# ESP32-C61 register map
Vendor: ESPRESSIF SYSTEMS (SHANGHAI) CO., LTD.; Series: ESP32 C-Series; File version: 1
CPU: RV32IMAC r0p0, little endian, no MPU, no FPU, 0 interrupt priority bits
Address unit: 32 bits
Registers are 32-bit, read-write, reset 0x0 unless marked. A register's access mark holds for its fields unless they carry their own. Offsets are from the block's base; [hi:lo] are bit positions.

## BUS_MONITOR — BUS_MONITOR Peripheral
Base 0x600C2000
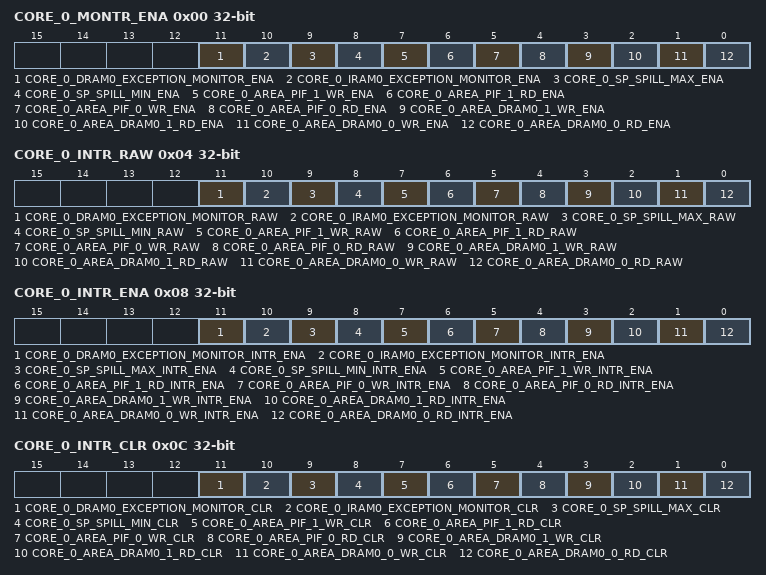
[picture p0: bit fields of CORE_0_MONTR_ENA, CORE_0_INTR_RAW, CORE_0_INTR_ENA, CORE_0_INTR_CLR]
0x00 CORE_0_MONTR_ENA — core0 monitor enable configuration register
  [11] CORE_0_DRAM0_EXCEPTION_MONITOR_ENA — DBUS busy monitor enbale
  [10] CORE_0_IRAM0_EXCEPTION_MONITOR_ENA — IBUS busy monitor enable
  [9] CORE_0_SP_SPILL_MAX_ENA — Configures whether to monitor SP exceeding the upper bound address of SP monitored region.\\ 0: Not Monitor\\ 1: Monitor\\
  [8] CORE_0_SP_SPILL_MIN_ENA — Configures whether to monitor SP exceeding the lower bound address of SP monitored region.\\ 0: Not Monitor\\ 1: Monitor\\
  [7] CORE_0_AREA_PIF_1_WR_ENA — Configures whether to monitor write operations in region 1 by the Peripheral bus.\\ 0: Not Monitor\\ 1: Monitor\\
  [6] CORE_0_AREA_PIF_1_RD_ENA — Configures whether to monitor read operations in region 1 by the Peripheral bus.\\ 0: Not Monitor\\ 1: Monitor\\
  [5] CORE_0_AREA_PIF_0_WR_ENA — Configures whether to monitor write operations in region 0 by the Peripheral bus.\\ 0: Not Monitor\\ 1: Monitor\\
  [4] CORE_0_AREA_PIF_0_RD_ENA — Configures whether to monitor read operations in region 0 by the Peripheral bus.\\ 0: Not Monitor\\ 1: Monitor\\
  [3] CORE_0_AREA_DRAM0_1_WR_ENA — Configures whether to monitor write operations in region 1 by the Data bus.\\ 0: Not Monitor\\ 1: Monitor\\
  [2] CORE_0_AREA_DRAM0_1_RD_ENA — Configures whether to monitor read operations in region 1 by the Data bus.\\ 0: Not Monitor\\ 1: Monitor\\
  [1] CORE_0_AREA_DRAM0_0_WR_ENA — Configures whether to monitor write operations in region 0 by the Data bus.\\ 0: Not monitor\\ 1: Monitor\\
  [0] CORE_0_AREA_DRAM0_0_RD_ENA — Configures whether to monitor read operations in region 0 by the Data bus. \\ 0: Not monitor\\ 1: Monitor\\
0x04 CORE_0_INTR_RAW ro — core0 monitor interrupt status register
  [11] CORE_0_DRAM0_EXCEPTION_MONITOR_RAW — DBUS busy monitor initerrupt status
  [10] CORE_0_IRAM0_EXCEPTION_MONITOR_RAW — IBUS busy monitor interrupt status
  [9] CORE_0_SP_SPILL_MAX_RAW — The raw interrupt status of SP exceeding the upper bound address of SP monitored region.
  [8] CORE_0_SP_SPILL_MIN_RAW — The raw interrupt status of SP exceeding the lower bound address of SP monitored region.
  [7] CORE_0_AREA_PIF_1_WR_RAW — The raw interrupt status of write operations in region 1 by Peripheral bus.
  [6] CORE_0_AREA_PIF_1_RD_RAW — The raw interrupt status of read operations in region 1 by Peripheral bus.
  [5] CORE_0_AREA_PIF_0_WR_RAW — The raw interrupt status of write operations in region 0 by Peripheral bus.
  [4] CORE_0_AREA_PIF_0_RD_RAW — The raw interrupt status of read operations in region 0 by Peripheral bus.
  [3] CORE_0_AREA_DRAM0_1_WR_RAW — The raw interrupt status of write operations in region 1 by Data bus.
  [2] CORE_0_AREA_DRAM0_1_RD_RAW — The raw interrupt status of read operations in region 1 by Data bus.
  [1] CORE_0_AREA_DRAM0_0_WR_RAW — The raw interrupt status of write operations in region 0 by Data bus.
  [0] CORE_0_AREA_DRAM0_0_RD_RAW — The raw interrupt status of read operations in region 0 by Data bus.
0x08 CORE_0_INTR_ENA — core0 monitor interrupt enable register
  [11] CORE_0_DRAM0_EXCEPTION_MONITOR_INTR_ENA — DBUS busy monitor interrupt enbale
  [10] CORE_0_IRAM0_EXCEPTION_MONITOR_INTR_ENA — IBUS busy monitor interrupt enable
  [9] CORE_0_SP_SPILL_MAX_INTR_ENA — Core0 stackpoint overflow monitor interrupt enable
  [8] CORE_0_SP_SPILL_MIN_INTR_ENA — Core0 stackpoint underflow monitor interrupt enable
  [7] CORE_0_AREA_PIF_1_WR_INTR_ENA — Core0 PIF area1 write monitor interrupt enable
  [6] CORE_0_AREA_PIF_1_RD_INTR_ENA — Core0 PIF area1 read monitor interrupt enable
  [5] CORE_0_AREA_PIF_0_WR_INTR_ENA — Core0 PIF area0 write monitor interrupt enable
  [4] CORE_0_AREA_PIF_0_RD_INTR_ENA — Core0 PIF area0 read monitor interrupt enable
  [3] CORE_0_AREA_DRAM0_1_WR_INTR_ENA — Core0 dram0 area1 write monitor interrupt enable
  [2] CORE_0_AREA_DRAM0_1_RD_INTR_ENA — Core0 dram0 area1 read monitor interrupt enable
  [1] CORE_0_AREA_DRAM0_0_WR_INTR_ENA — Core0 dram0 area0 write monitor interrupt enable
  [0] CORE_0_AREA_DRAM0_0_RD_INTR_ENA — Core0 dram0 area0 read monitor interrupt enable
0x0C CORE_0_INTR_CLR wo — core0 monitor interrupt clear register
  [11] CORE_0_DRAM0_EXCEPTION_MONITOR_CLR — DBUS busy monitor interrupt clr
  [10] CORE_0_IRAM0_EXCEPTION_MONITOR_CLR — IBUS busy monitor interrupt clr
  [9] CORE_0_SP_SPILL_MAX_CLR — Write 1 to clear the interrupt for SP exceeding the upper bound address of SP monitored region.
  [8] CORE_0_SP_SPILL_MIN_CLR — Write 1 to clear the interrupt for SP exceeding the lower bound address of SP monitored region.
  [7] CORE_0_AREA_PIF_1_WR_CLR — Write 1 to clear the interrupt for write operations in region 1 by Peripheral bus.
  [6] CORE_0_AREA_PIF_1_RD_CLR — Write 1 to clear the interrupt for read operations in region 1 by Peripheral bus.
  [5] CORE_0_AREA_PIF_0_WR_CLR — Write 1 to clear the interrupt for write operations in region 0 by Peripheral bus.
  [4] CORE_0_AREA_PIF_0_RD_CLR — Write 1 to clear the interrupt for read operations in region 0 by Peripheral bus.
  [3] CORE_0_AREA_DRAM0_1_WR_CLR — Write 1 to clear the interrupt for write operations in region 1 by Data bus.
  [2] CORE_0_AREA_DRAM0_1_RD_CLR — Write 1 to clear the interrupt for read operations in region 1 by Data bus.
  [1] CORE_0_AREA_DRAM0_0_WR_CLR — Write 1 to clear the interrupt for write operations in region 0 by Data bus.
  [0] CORE_0_AREA_DRAM0_0_RD_CLR — Write 1 to clear the interrupt for read operations in region 0 by Data bus.
0x10 CORE_0_AREA_DRAM0_0_MIN reset 0xFFFFFFFF — Configures lower boundary address of region 0 monitored on Data bus
  [31:0] CORE_0_AREA_DRAM0_0_MIN — Configures the lower bound address of Data bus region 0.
0x14 CORE_0_AREA_DRAM0_0_MAX — Configures upper boundary address of region 0 monitored on Data bus
  [31:0] CORE_0_AREA_DRAM0_0_MAX — Configures the upper bound address of Data bus region 0.
0x18 CORE_0_AREA_DRAM0_1_MIN reset 0xFFFFFFFF — Configures lower boundary address of region 1 monitored on Data bus
  [31:0] CORE_0_AREA_DRAM0_1_MIN — Configures the lower bound address of Data bus region 1.
0x1C CORE_0_AREA_DRAM0_1_MAX — Configures upper boundary address of region 1 monitored on Data bus
  [31:0] CORE_0_AREA_DRAM0_1_MAX — Configures the upper bound address of Data bus region 1.
0x20 CORE_0_AREA_PIF_0_MIN reset 0xFFFFFFFF — Configures lower boundary address of region 0 monitored on Peripheral bus
  [31:0] CORE_0_AREA_PIF_0_MIN — Configures the lower bound address of Peripheral bus region 0.
0x24 CORE_0_AREA_PIF_0_MAX — Configures upper boundary address of region 0 monitored on Peripheral bus
  [31:0] CORE_0_AREA_PIF_0_MAX — Configures the upper bound address of Peripheral bus region 0.
0x28 CORE_0_AREA_PIF_1_MIN reset 0xFFFFFFFF — Configures lower boundary address of region 1 monitored on Peripheral bus
  [31:0] CORE_0_AREA_PIF_1_MIN — Configures the lower bound address of Peripheral bus region 1.
0x2C CORE_0_AREA_PIF_1_MAX — Configures upper boundary address of region 1 monitored on Peripheral bus
  [31:0] CORE_0_AREA_PIF_1_MAX — Configures the upper bound address of Peripheral bus region 1.
0x30 CORE_0_AREA_PC ro — Region monitoring HP CPU PC status register
  [31:0] CORE_0_AREA_PC — Represents the PC value when an interrupt is triggered during region monitoring.
0x34 CORE_0_AREA_SP ro — Region monitoring HP CPU SP status register
  [31:0] CORE_0_AREA_SP — Represents the SP value when an interrupt is triggered during region monitoring.
0x38 CORE_0_SP_MIN — Configures stack monitoring lower boundary address
  [31:0] CORE_0_SP_MIN — Configures the lower bound address of SP.
0x3C CORE_0_SP_MAX reset 0xFFFFFFFF — Configures stack monitoring upper boundary address
  [31:0] CORE_0_SP_MAX — Configures the upper bound address of SP.
0x40 CORE_0_SP_PC ro — Stack monitoring HP CPU PC status register
  [31:0] CORE_0_SP_PC — Represents the PC value during stack monitoring.
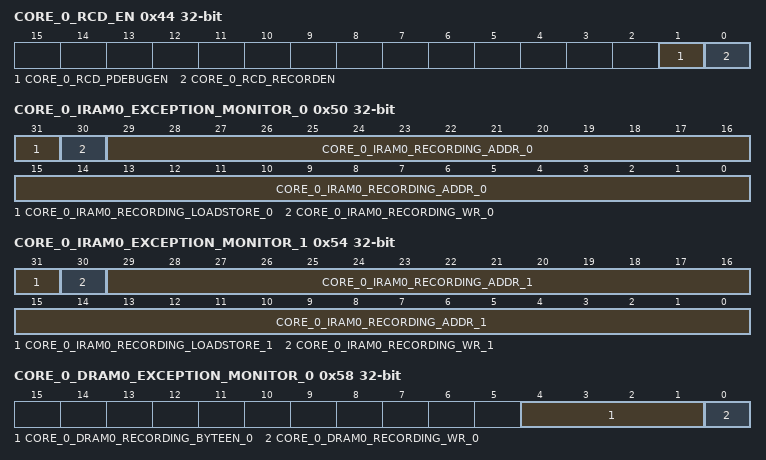
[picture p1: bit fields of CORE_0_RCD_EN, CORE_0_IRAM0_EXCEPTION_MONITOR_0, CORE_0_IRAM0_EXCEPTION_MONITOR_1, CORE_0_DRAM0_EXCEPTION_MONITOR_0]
0x44 CORE_0_RCD_EN — HP CPU PC logging enable register
  [1] CORE_0_RCD_PDEBUGEN — Configures whether to enable HP CPU debugging.\\ 0: Disable\\ 1: HP CPU outputs PC\\
  [0] CORE_0_RCD_RECORDEN — Configures whether to enable PC logging.\\ 0: Disable\\ 1: ASSIST_DEBUG_CORE_0_RCD_PDEBUGPC_REG starts to record PC in real time\\
0x48 CORE_0_RCD_PDEBUGPC ro — PC logging register
  [31:0] CORE_0_RCD_PDEBUGPC — Represents the PC value at HP CPU reset.
0x4C CORE_0_RCD_PDEBUGSP ro — PC logging register
  [31:0] CORE_0_RCD_PDEBUGSP — Represents SP.
0x50 CORE_0_IRAM0_EXCEPTION_MONITOR_0 ro — exception monitor status register0
  [31] CORE_0_IRAM0_RECORDING_LOADSTORE_0 — reg_core_0_iram0_recording_loadstore_0
  [30] CORE_0_IRAM0_RECORDING_WR_0 — reg_core_0_iram0_recording_wr_0
  [29:0] CORE_0_IRAM0_RECORDING_ADDR_0 — reg_core_0_iram0_recording_addr_0
0x54 CORE_0_IRAM0_EXCEPTION_MONITOR_1 ro — exception monitor status register1
  [31] CORE_0_IRAM0_RECORDING_LOADSTORE_1 — reg_core_0_iram0_recording_loadstore_1
  [30] CORE_0_IRAM0_RECORDING_WR_1 — reg_core_0_iram0_recording_wr_1
  [29:0] CORE_0_IRAM0_RECORDING_ADDR_1 — reg_core_0_iram0_recording_addr_1
0x58 CORE_0_DRAM0_EXCEPTION_MONITOR_0 ro — exception monitor status register2
  [4:1] CORE_0_DRAM0_RECORDING_BYTEEN_0 — reg_core_0_dram0_recording_byteen_0
  [0] CORE_0_DRAM0_RECORDING_WR_0 — reg_core_0_dram0_recording_wr_0
0x5C CORE_0_DRAM0_EXCEPTION_MONITOR_1 ro — exception monitor status register3
  [29:0] CORE_0_DRAM0_RECORDING_ADDR_0 — reg_core_0_dram0_recording_addr_0
0x60 CORE_0_DRAM0_EXCEPTION_MONITOR_2 ro — exception monitor status register4
  [31:0] CORE_0_DRAM0_RECORDING_PC_0 — reg_core_0_dram0_recording_pc_0
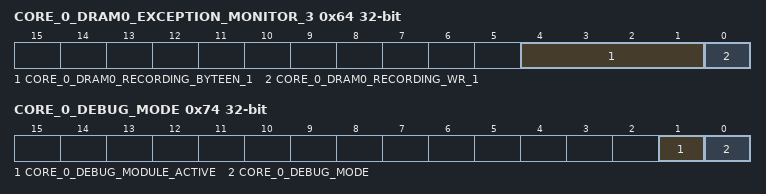
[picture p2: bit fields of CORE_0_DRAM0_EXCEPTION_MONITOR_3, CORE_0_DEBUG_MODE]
0x64 CORE_0_DRAM0_EXCEPTION_MONITOR_3 ro — exception monitor status register5
  [4:1] CORE_0_DRAM0_RECORDING_BYTEEN_1 — reg_core_0_dram0_recording_byteen_1
  [0] CORE_0_DRAM0_RECORDING_WR_1 — reg_core_0_dram0_recording_wr_1
0x68 CORE_0_DRAM0_EXCEPTION_MONITOR_4 ro — exception monitor status register6
  [29:0] CORE_0_DRAM0_RECORDING_ADDR_1 — reg_core_0_dram0_recording_addr_1
0x6C CORE_0_DRAM0_EXCEPTION_MONITOR_5 ro — exception monitor status register7
  [31:0] CORE_0_DRAM0_RECORDING_PC_1 — reg_core_0_dram0_recording_pc_1
0x70 CORE_0_LASTPC_BEFORE_EXCEPTION ro — cpu status register
  [31:0] CORE_0_LASTPC_BEFORE_EXC — Represents the PC of the last command before the HP CPU enters exception.
0x74 CORE_0_DEBUG_MODE ro — cpu status register
  [1] CORE_0_DEBUG_MODULE_ACTIVE — Represents the status of the RISC-V CPU (HP CPU) debug module.\\ 1: Active status\\ Other: Inactive status\\
  [0] CORE_0_DEBUG_MODE — Represents whether RISC-V CPU (HP CPU) is in debugging mode.\\ 1: In debugging mode\\ 0: Not in debugging mode\\
0x100 CORE_X_IRAM0_DRAM0_EXCEPTION_MONITOR_0 — exception monitor status register8
  [19:0] CORE_X_IRAM0_DRAM0_LIMIT_CYCLE_0 — reg_core_x_iram0_dram0_limit_cycle_0
0x104 CORE_X_IRAM0_DRAM0_EXCEPTION_MONITOR_1 — exception monitor status register9
  [19:0] CORE_X_IRAM0_DRAM0_LIMIT_CYCLE_1 — reg_core_x_iram0_dram0_limit_cycle_1
0x108 CLOCK_GATE reset 0x1 — Register clock control
  [0] CLK_EN — Configures whether to enable the register clock gating. \\ 0: Disable\\ 1: Enable\\
0x3FC DATE reset 0x2109130 — Version control register
  [27:0] DATE — version register
